AUTOSAR XML (schema 4-0-3)
standard types defined: Boolean, UInt32
package /AUTOSAR_Platform/DataConstrs
  range DC_Boolean: raw 0..1
package /PATAC/Facility/DataTypes/Implementation
  compu method COMPU_Boolean: 0=FALSE, 1=TRUE
  unit NoUnit: factor-si-to-unit=1, offset-si-to-unit=0
package /PATAC/MSM/ComponentTypes
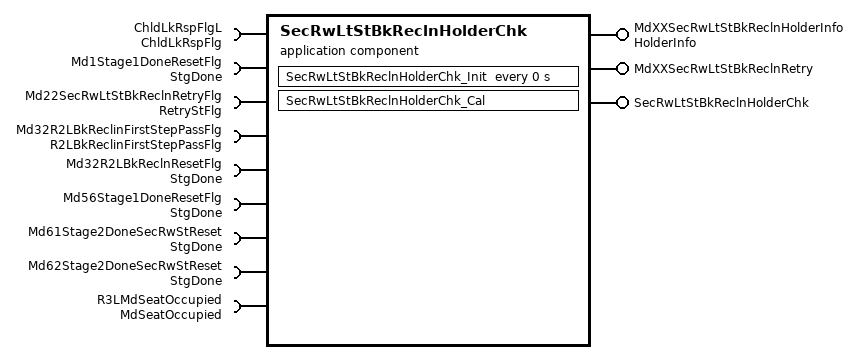
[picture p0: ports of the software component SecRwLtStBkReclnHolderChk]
  application sw component type SecRwLtStBkReclnHolderChk
    provide port MdXXSecRwLtStBkReclnHolderInfo: nonqueued-sender-com-spec{data-element=HolderInfo/Val, init-value=0}, provided-interface=HolderInfo
    provide port MdXXSecRwLtStBkReclnRetry: nonqueued-sender-com-spec{data-element=MdXXSecRwLtStBkReclnRetry/Val, init-value=0}, provided-interface=MdXXSecRwLtStBkReclnRetry
    provide port SecRwLtStBkReclnHolderChk: server-com-spec{operation=Cal, queue-length=1}, provided-interface=SecRwLtStBkReclnHolderChk
    9 x require port:
      ChldLkRspFlgL: nonqueued-receiver-com-spec{data-element=ChldLkRspFlg/Val, filter=data-filter-type=ALWAYS, init-value=0}, required-interface=ChldLkRspFlg
      Md1Stage1DoneResetFlg: nonqueued-receiver-com-spec{data-element=StgDone/Val, filter=data-filter-type=ALWAYS, init-value=0}, required-interface=StgDone
      Md22SecRwLtStBkReclnRetryFlg: nonqueued-receiver-com-spec{data-element=RetryStFlg/Val, filter=data-filter-type=ALWAYS, init-value=0}, required-interface=RetryStFlg
      Md32R2LBkReclinFirstStepPassFlg: nonqueued-receiver-com-spec{data-element=R2LBkReclinFirstStepPassFlg/Val, filter=data-filter-type=ALWAYS, init-value=0}, required-interface=R2LBkReclinFirstStepPassFlg
      Md32R2LBkReclnResetFlg: nonqueued-receiver-com-spec{data-element=StgDone/Val, filter=data-filter-type=ALWAYS, init-value=0}, required-interface=StgDone
      Md56Stage1DoneResetFlg: nonqueued-receiver-com-spec{data-element=StgDone/Val, filter=data-filter-type=ALWAYS, init-value=0}, required-interface=StgDone
      Md61Stage2DoneSecRwStReset: nonqueued-receiver-com-spec{data-element=StgDone/Val, filter=data-filter-type=ALWAYS, init-value=0}, required-interface=StgDone
      Md62Stage2DoneSecRwStReset: nonqueued-receiver-com-spec{data-element=StgDone/Val, filter=data-filter-type=ALWAYS, init-value=0}, required-interface=StgDone
      R3LMdSeatOccupied: nonqueued-receiver-com-spec{data-element=MdSeatOccupied/Val, filter=data-filter-type=ALWAYS, init-value=0}, required-interface=MdSeatOccupied
    behavior SecRwLtStBkReclnHolderChk_InternalBehavior
      operation invoked event OIT_SecRwLtStBkReclnHolderChk_Cal_SecRwLtStBkReclnHolderChk_Cal: start-on-event=SecRwLtStBkReclnHolderChk_Cal, operation=SecRwLtStBkReclnHolderChk.Cal
      timing event SecRwLtStBkReclnHolderChk_InitEvent: start-on-event=SecRwLtStBkReclnHolderChk_Init, period=0
      runnable SecRwLtStBkReclnHolderChk_Cal
        data-receive-point-by-arguments:
          9 x access:
            REC_ChldLkRspFlgL_Val: accessed-variable=ChldLkRspFlgL.Val
            REC_Md1Stage1DoneResetFlg_Val: accessed-variable=Md1Stage1DoneResetFlg.Val
            REC_Md22SecRwLtStBkReclnRetryFlg_Val: accessed-variable=Md22SecRwLtStBkReclnRetryFlg.Val
            REC_Md32R2LBkReclinFirstStepPassFlg_Val: accessed-variable=Md32R2LBkReclinFirstStepPassFlg.Val
            REC_Md32R2LBkReclnResetFlg_Val: accessed-variable=Md32R2LBkReclnResetFlg.Val
            REC_Md56Stage1DoneResetFlg_Val: accessed-variable=Md56Stage1DoneResetFlg.Val
            REC_Md61Stage2DoneSecRwStReset_Val: accessed-variable=Md61Stage2DoneSecRwStReset.Val
            REC_Md62Stage2DoneSecRwStReset_Val: accessed-variable=Md62Stage2DoneSecRwStReset.Val
            REC_R3LMdSeatOccupied_Val: accessed-variable=R3LMdSeatOccupied.Val
        data-send-points:
          access SEND_MdXXSecRwLtStBkReclnHolderInfo_Val: accessed-variable=MdXXSecRwLtStBkReclnHolderInfo.Val
          access SEND_MdXXSecRwLtStBkReclnRetry_Val: accessed-variable=MdXXSecRwLtStBkReclnRetry.Val
      runnable SecRwLtStBkReclnHolderChk_Init
  swc implementation SecRwLtStBkReclnHolderChk_Implementation: behavior=SecRwLtStBkReclnHolderChk_InternalBehavior
    code-descriptors:
      code Default: artifact-descriptors=autosar-engineering-object={short-label=Default, category=SWSRC}
package /PATAC/MSM/ModeAdjust/PortInterface
  client server interface SecRwLtStBkReclnHolderChk
    operation Cal
  7 x sender receiver interface:
    ChldLkRspFlg: invalidation-policy{data-element=ChldLkRspFlg/Val, handle-invalid=DONT-INVALIDATE}
      data Val: type=Boolean
    HolderInfo: invalidation-policy{data-element=HolderInfo/Val, handle-invalid=DONT-INVALIDATE}
      data Val: type=UInt32
    MdSeatOccupied: invalidation-policy{data-element=MdSeatOccupied/Val, handle-invalid=DONT-INVALIDATE}
      data Val: type=Boolean
    MdXXSecRwLtStBkReclnRetry: invalidation-policy{data-element=MdXXSecRwLtStBkReclnRetry/Val, handle-invalid=DONT-INVALIDATE}
      data Val: type=UInt32
    R2LBkReclinFirstStepPassFlg: invalidation-policy{data-element=R2LBkReclinFirstStepPassFlg/Val, handle-invalid=DONT-INVALIDATE}
      data Val: type=Boolean
    RetryStFlg: invalidation-policy{data-element=RetryStFlg/Val, handle-invalid=DONT-INVALIDATE}
      data Val: type=Boolean
    StgDone: invalidation-policy{data-element=StgDone/Val, handle-invalid=DONT-INVALIDATE}
      data Val: type=Boolean
